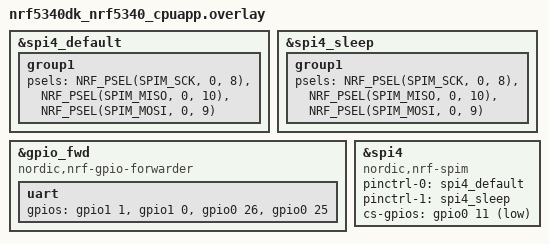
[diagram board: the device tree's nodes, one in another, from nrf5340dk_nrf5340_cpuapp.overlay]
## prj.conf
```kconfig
CONFIG_PRINTK=y

CONFIG_SPI=y
CONFIG_SPI_NRFX=y
CONFIG_NRFX_SPIM2=y
#CONFIG_NRFX_SPIM4=y
```

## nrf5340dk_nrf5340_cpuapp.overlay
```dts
// To get started, press Ctrl+Space to bring up the completion menu and view the available nodes.

// You can also use the buttons in the sidebar to perform actions on nodes.
// Actions currently available include:

// * Enabling / disabling the node
// * Adding the bus to a bus
// * Removing the node
// * Connecting ADC channels

// For more help, browse the DeviceTree documentation at https://docs.zephyrproject.org/latest/guides/dts/index.html
// You can also visit the nRF DeviceTree extension documentation at https://nrfconnect.github.io/vscode-nrf-connect/devicetree/nrfdevicetree.html
/* Modify SPI 4 to use GPIO0 pins 8,9,10 for SCK, MOSI, and MISO respectively. */

/* Modify SPI 4 to use GPIO0 pins 8,9,10 for SCK, MOSI, and MISO respectively. */
&spi4_default {
	group1 {
		psels = <NRF_PSEL(SPIM_SCK, 0, 8)>,
			<NRF_PSEL(SPIM_MISO, 0, 10)>,
			<NRF_PSEL(SPIM_MOSI, 0, 9)>;
	};
};

&spi4_sleep {
	group1 {
		psels = <NRF_PSEL(SPIM_SCK, 0, 8)>,
			<NRF_PSEL(SPIM_MISO, 0, 10)>,
			<NRF_PSEL(SPIM_MOSI, 0, 9)>;
	};
};


/* This is needed because the default setting for UART uses GPIO0_10 and GPIO0_11 which we need to use for SPI.*/
&gpio_fwd {
	compatible = "nordic,nrf-gpio-forwarder";
	status = "okay";
	uart {
		gpios = <&gpio1 1 0>, <&gpio1 0 0>, <&gpio0 26 0>, <&gpio0 25 0>;
	};
};

&spi4 {
	compatible = "nordic,nrf-spim";
	status = "okay";
	pinctrl-0 = <&spi4_default>;
	pinctrl-1 = <&spi4_sleep>;
	pinctrl-names = "default", "sleep";
    cs-gpios = <&gpio0 11 GPIO_ACTIVE_LOW>;
};

// &spi2 {
// 	compatible = "nordic,nrf-spim";
// 	status = "okay";
// 	pinctrl-0 = <&spi2_default>;
// 	pinctrl-1 = <&spi2_sleep>;
// 	pinctrl-names = "default", "sleep";
//     cs-gpios = <&gpio0 12 GPIO_ACTIVE_LOW>;
// };

// &spi3{
// 	compatible = "nordic,nrf-spim";
// 	status = "okay";
// 	pinctrl-0 = <&spi3_default>;
// 	pinctrl-names = "default";
// 	cs-gpios = <&gpio1 7 GPIO_ACTIVE_LOW>;
// };
```

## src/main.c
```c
#include <zephyr.h>
#include <stdio.h>
#include <string.h>
#include <nrfx_spim.h>

#define SPIM_SCLK         (37)      //p1.05
#define SPIM_MOSI         (47)
#define SPIM_MISO         (45)
#define SPIM_SS           (43)


// #define SPIM_SCLK         (8)
// #define SPIM_MOSI         (9)
// #define SPIM_MISO         (10)
// #define SPIM_SS           (11)

static const nrfx_spim_t spi_dev = NRFX_SPIM_INSTANCE(2);

void spi_init(void) {

    nrfx_err_t err;
    nrfx_spim_uninit(&spi_dev);
    nrfx_spim_config_t config = NRFX_SPIM_DEFAULT_CONFIG(SPIM_SCLK,SPIM_MOSI,SPIM_MISO,SPIM_SS);
    config.frequency = NRF_SPIM_FREQ_4M;
    //config.miso_pull = GPIO_PIN_CNF_PULL_Pulldown;
	err = nrfx_spim_init(&spi_dev, &config, NULL, NULL);
	if (err != NRFX_SUCCESS) {
		printk("Failed to initialize SPI: 0x%08X\n", err);
		return;
	}
}

void spi_send_receive(uint8_t * send_buf, size_t send_length, uint8_t * recv_buf, size_t recv_length) {
    int err = 0;

    nrfx_spim_xfer_desc_t xfer_desc = NRFX_SPIM_XFER_TRX(send_buf, send_length, recv_buf, recv_length);

    err = nrfx_spim_xfer(&spi_dev, &xfer_desc, 0);
	if (err != NRFX_SUCCESS) {
		printk("Transfer failed: 0x%08X\n", err);
	}
}

void main(void){
    k_msleep(5000);
    printk("start\n");
    spi_init();
    uint8_t intdata[2] = {0x03, 0x10};
    uint8_t tx_data[5] = {0x80, 0x83, 0x85, 0x86, 0x00};
    uint8_t rx_data[5] = {0x00};
    spi_send_receive(intdata, 2, NULL, 0);
    k_msleep(1000);
    while (1){ 
        spi_send_receive(tx_data, 5, rx_data, 5);
        printk("data: %x,%x,%x,%x,%x\n",rx_data[0],rx_data[1],rx_data[2],rx_data[3],rx_data[4]);
        // Wait
        k_msleep(1000);
    }
}
```

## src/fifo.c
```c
/*
 * Copyright (c) 2012-2014 Wind River Systems, Inc.
 *
 * SPDX-License-Identifier: Apache-2.0
 */

#include <zephyr.h>
#include <zephyr/kernel.h>

K_FIFO_DEFINE(fifo_test);

struct data_type_t{
	void *fifo_reserved;
	uint8_t data_content;
};

struct data_type_t* tx_data = NULL;
struct data_type_t* rx_data = NULL;
int x=0;

void add_data_fifo(){
	tx_data = k_malloc(sizeof(*tx_data));
	tx_data->data_content = x;
	k_fifo_put(&fifo_test, tx_data);
	x++;
}

void main(void)
{
	k_sleep(K_SECONDS(1));
	for(int x=0;x<5;x++){
		add_data_fifo();
	}
	int x = 0;
	while(1){
		if(!k_fifo_is_empty(&fifo_test)){
			rx_data = k_fifo_get(&fifo_test,K_FOREVER);
			printk("%d ", x);
			printk("output: rx_data (%d)\n", rx_data->data_content);
			x++;
			k_free(rx_data);
		}
		k_sleep(K_MSEC(500));
	}
}
```

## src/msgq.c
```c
#include <zephyr.h>
#include <zephyr/kernel.h>

K_MSGQ_DEFINE(my_msgq, sizeof(uint8_t), 10, 4);

void data_producer(){
    uint8_t data;
    k_msgq_put(&my_msgq, &data, K_NO_WAIT);
}

void main(void){

}
```

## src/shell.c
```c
#include <zephyr.h>
#include <zephyr/kernel.h>
#include <zephyr/shell/shell.h>

static int cmd_demo_ping(const struct shell *sh, size_t argc, char **argv){
    printk("pong\n");
}

SHELL_STATIC_SUBCMD_SET_CREATE(sub_demo,
    SHELL_CMD(ping, NULL, "PING command", cmd_demo_ping),
    SHELL_SUBCMD_SET_END
);

SHELL_CMD_REGISTER(demo, &sub_demo, "DEMO COMMANDS", NULL);

void main(void){
    printk("init\n");
}
```

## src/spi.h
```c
#pragma once

#include <stdint.h>
#include <stdio.h>
#include <nrfx_spim.h>

/* Configurations SPI, must match .overlay file for the chip. */
#define CONFIG_SPI_NAME               "SPI_4"  // Using SPI 4, the only high speed spi
#define CONFIG_SPI_SCK_PIN            8  // TODO: can we somehow retrieve these values from the .overlay file instead of having it hardcoded here ?
#define CONFIG_SPI_MOSI_PIN           9
#define CONFIG_SPI_MISO_PIN           10
#define CONFIG_SPI_CS_CTRL_GPIO_DEV   "GPIO_0"
#define CONFIG_SPI_CS_CTRL_GPIO_PIN   11  
#define CONFIG_SPI_FREQ_HZ            8000000
#define CONFIG_SPI_FREQ_NRF           NRF_SPIM_FREQ_16M

typedef struct spi_priv_t {
    bool is_initialized;
    nrfx_spim_t spi;
} spi_priv_t;

void spi_init(void);
void spi_test_send(void);
bool spi_is_initialized(void);
int spi_send_receive(uint8_t * send_buf, size_t send_length, uint8_t * recv_buf, size_t recv_length);

// void spi1_init(void);
```

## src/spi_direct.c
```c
#include <drivers/gpio.h>
#include <logging/log.h>
#include <nrfx_spim.h>

#define LOG_MODULE_NAME         nordic_spi_direct_c
LOG_MODULE_REGISTER(LOG_MODULE_NAME, LOG_LEVEL_ERR);

#include "spi.h"

#define SPI_NODE  DT_NODELABEL(spi4)

spi_priv_t spi_priv;

void spi_init(void) {

    spi_priv.spi = (nrfx_spim_t) NRFX_SPIM_INSTANCE(4);
    nrfx_err_t err;

    nrfx_spim_config_t config = NRFX_SPIM_DEFAULT_CONFIG(
		CONFIG_SPI_SCK_PIN,
        CONFIG_SPI_MOSI_PIN,
        CONFIG_SPI_MISO_PIN,
		NRF_DT_GPIOS_TO_PSEL(SPI_NODE, cs_gpios));
	config.frequency = NRF_SPIM_FREQ_4M;
	config.mode = NRF_SPIM_MODE_0;

	err = nrfx_spim_init(&spi_priv.spi, &config, NULL, NULL);
	if (err != NRFX_SUCCESS) {
		LOG_ERR("Failed to initialize SPI: 0x%08X\n", err);
		return;
	}

    spi_priv.is_initialized = true;
}


bool spi_is_initialized(void) {

    return spi_priv.is_initialized;
}

int spi_send_receive(uint8_t * send_buf, size_t send_length, uint8_t * recv_buf, size_t recv_length) {
    int err = 0;

    nrfx_spim_xfer_desc_t xfer_desc = {
        .p_tx_buffer = send_buf,
        .tx_length = send_length,
        .p_rx_buffer = recv_buf,
        .rx_length = recv_length,
    };

    err = nrfx_spim_xfer(&spi_priv.spi, &xfer_desc, 0);
	if (err != NRFX_SUCCESS) {
		LOG_ERR("Transfer failed: 0x%08X\n", err);
        return err;
	}
    else {
        return 0; //TODO: Fix this, it would be nice if upper level application is aware of NRFX error codes. But callers are now expecting 0.
    }
}

void spi_test_send(void) {
	uint8_t tx_buffer[4] = {0x80, 0x80, 0x80, 0x80};
	uint8_t rx_buffer[4] = {0xFF, 0xF0, 0x0F, 0x00};

    spi_send_receive(tx_buffer, 4, NULL, 0);
}

// nrfx_spim_t spi1_dev = NRFX_SPIM_INSTANCE(1);

// void spi1_init (void){
//     nrfx_spim_config_t spi1_config = NRFX_SPIM_DEFAULT_CONFIG(0,1,2,3);
//     nrfx_spim_uinit(&spi1_dev);    
//     int err = nrfx_spim_init(&spi1_dev, &spi1_config, NULL, NULL);
// 	if (err != NRFX_SUCCESS) {
// 		LOG_ERR("Failed to initialize SPI: 0x%08X\n", err);
// 		return;
// 	}
// }
```
